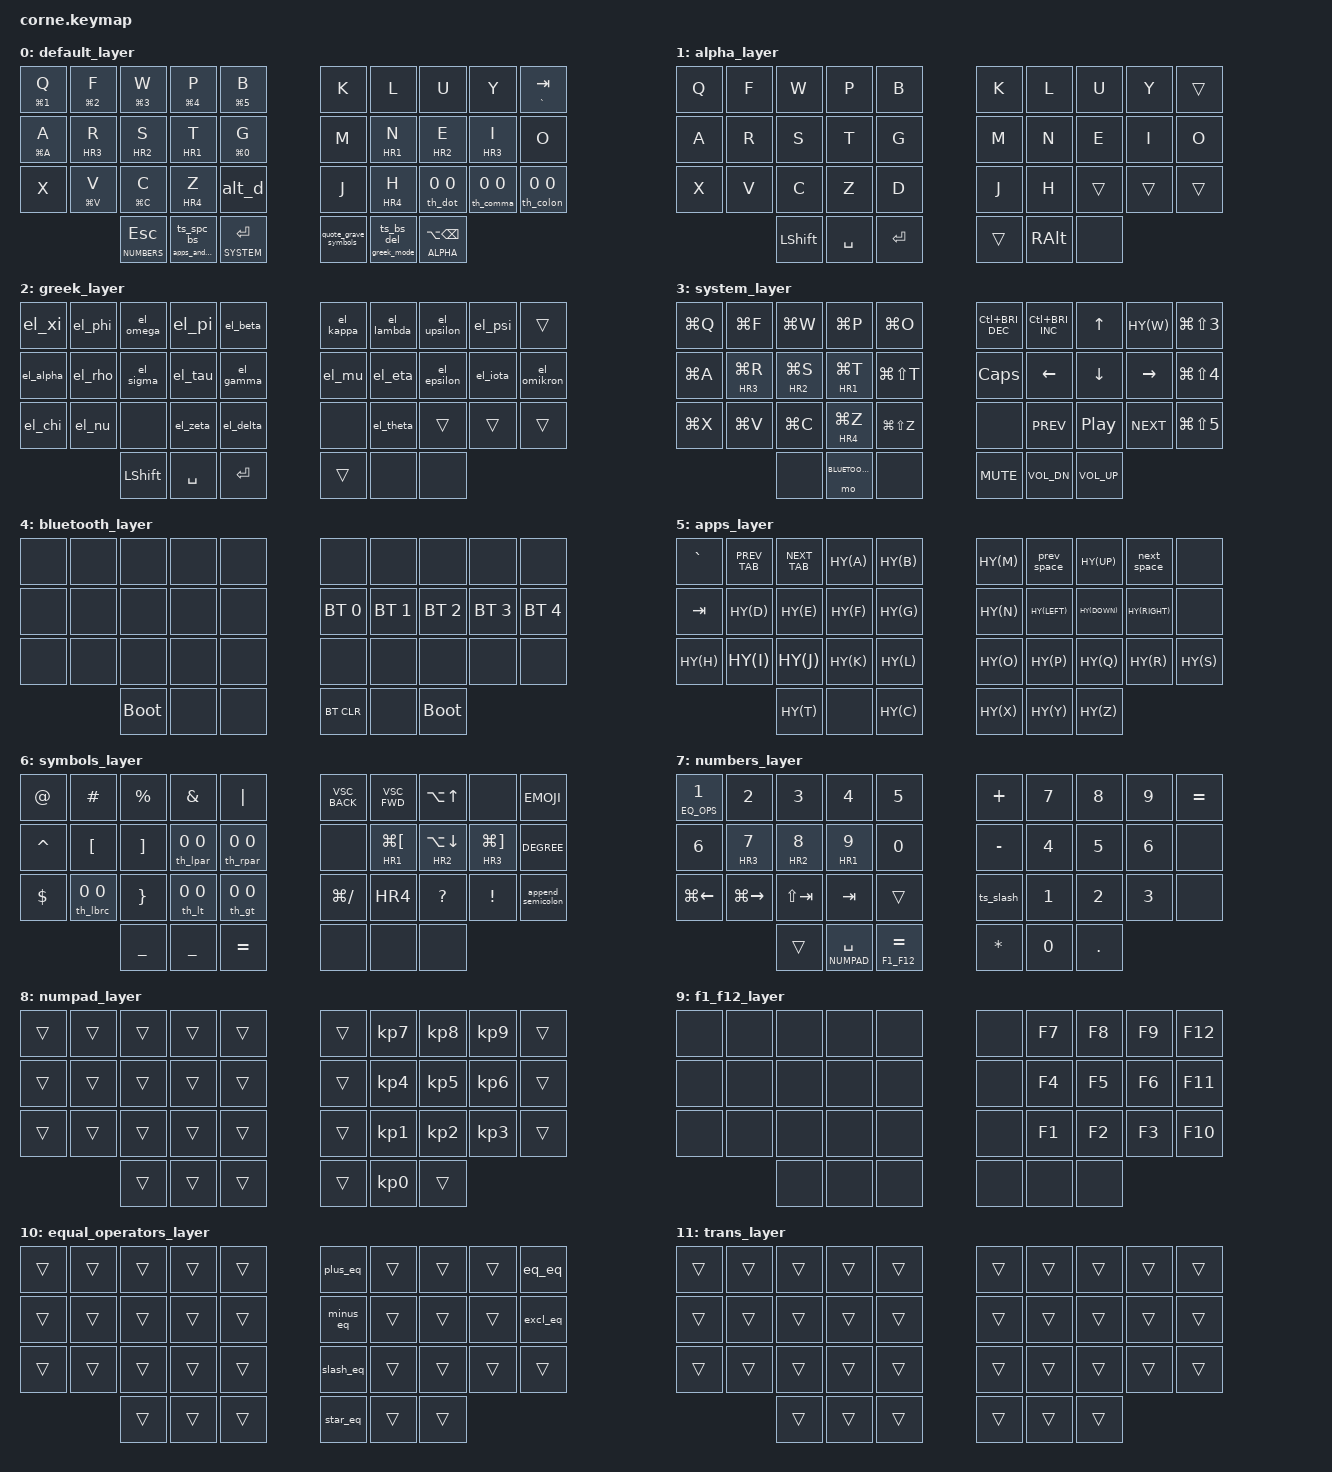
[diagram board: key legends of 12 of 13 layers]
#include <behaviors.dtsi>
#include <dt-bindings/zmk/keys.h>
#include <dt-bindings/zmk/bt.h>

#define HOST_OS 2
#include "zmk-helpers/helper.h"
#include "zmk-helpers/unicode-chars/greek.dtsi"

// layers
#define ALPHA 1
#define GREEK 2
#define SYSTEM 3
#define BLUETOOTH 4
#define APPS 5
#define SYMBOLS 6
#define NUMBERS 7
#define NUMPAD 8
#define F1_F12 9
#define EQ_OPS 10

// home row
#define HR1 LSHIFT
#define HR2 LCMD
#define HR3 RALT
#define HR4 LCTRL

#define PREV_TAB LG(LS(LBKT))
#define NEXT_TAB LG(LS(RBKT))

#define PREV_SPACE LC(LEFT)
#define NEXT_SPACE LC(RIGHT)

// VS Code
#define VSC_BACK LC(MINUS)
#define VSC_FWD LC(LS(MINUS))

#define HY(X) LA(LC(LG(LS(X))))
#define EMOJI LC(LG(SPACE))
#define DEGREE LA(LS(N8))


#define MAKE_TAP_SHIFT(name, tap, shift) \
    name: name { \
        compatible = "zmk,behavior-mod-morph"; \
        label = #name; \
        #binding-cells = <0>; \
        bindings = <&kp tap>, <&kp shift>; \
        mods = <(MOD_LSFT|MOD_RSFT)>; \
    };


#define MAKE_KP_MACRO(name, ...) \
    name: name { \
        label = #name; \
        compatible = "zmk,behavior-macro"; \
        #binding-cells = <0>; \
        wait-ms = <0>; \
        tap-ms = <0>; \
        bindings = <&macro_tap __VA_ARGS__>; \
    };


#define MAKE_EQ_MACRO(name, key) \
        MAKE_KP_MACRO(name, &kp SPACE &kp key &kp EQUAL &kp SPACE)


#define MAKE_TAP_HOLD(name, tap, hold) \
    name: name { \
        compatible = "zmk,behavior-hold-tap"; \
        label = #name; \
        #binding-cells = <2>; \
        flavor = "tap-preferred"; \
        tapping-term-ms = <200>; \
        bindings = <hold>, <tap>; \
    };


// fixes "system layer not activating" perceived bug
//
// > triggers the hold behavior when the tapping-term-ms has expired or another key is pressed
// > — https://zmk.dev/docs/behaviors/hold-tap#flavors
&lt {
    flavor = "hold-preferred";
};

// fixes "alt instead of apostrophe" bug
&mt {
    flavor = "tap-preferred";
};


/ {
    chosen {
        zmk,matrix_transform = &five_column_transform;
    };

    macros {
        // hold to enable apps layer and left command at the same time
        apps_and_lcmd: apps_and_lcmd {
            label = "apps_and_lcmd";
            compatible = "zmk,behavior-macro";
            #binding-cells = <0>;
            wait-ms = <0>;
            bindings
                = <&macro_press &mo APPS &kp LCMD>
                , <&macro_pause_for_release>
                , <&macro_release &mo APPS &kp LCMD>
                ;
        };

        // toggle unicode input mode and switch to the Greek layer
        greek_mode: greek_mode {
            label = "greek_mode";
            compatible = "zmk,behavior-macro";
            #binding-cells = <0>;
            wait-ms = <0>;
            bindings
                = <&macro_tap &kp HY(U)>  // Unicode (via Hammerspoon)
                , <&macro_press &mo GREEK>
                , <&macro_pause_for_release>
                , <&macro_release &mo GREEK>
                , <&macro_tap &kp HY(V)>  // Polish (via Hammerspoon)
                ;
        };


        MAKE_KP_MACRO(selfdot, &kp S &kp E &kp L &kp F &kp DOT)
        MAKE_KP_MACRO(thisdot, &kp T &kp H &kp I &kp S &kp DOT)
        MAKE_KP_MACRO(args0, &kp DOLLAR &kp N0 &kp DOT)
        MAKE_KP_MACRO(append_semicolon, &kp LG(RIGHT) &kp SEMICOLON)

        // macros for TypeScript "fat arrow": `() => { ... }`
        MAKE_KP_MACRO(short_arrow_close, &kp RIGHT &kp SPACE &kp EQUAL &kp GT &kp SPACE)
        MAKE_KP_MACRO(short_arrow, &kp LPAR &short_arrow_close)
        MAKE_KP_MACRO(fat_arrow_close, &short_arrow_close &kp LBRC &kp SPACE &kp LEFT &kp SPACE)
        MAKE_KP_MACRO(fat_arrow, &kp LPAR &fat_arrow_close)

        MAKE_KP_MACRO(braces, &kp LG(RIGHT) &kp SPACE &kp LBRC &kp ENTER)

        MAKE_EQ_MACRO(eq_eq, EQUAL)
        MAKE_EQ_MACRO(excl_eq, EXCLAMATION)
        MAKE_EQ_MACRO(plus_eq, PLUS)
        MAKE_EQ_MACRO(minus_eq, MINUS)
        MAKE_EQ_MACRO(slash_eq, SLASH)
        MAKE_EQ_MACRO(star_eq, ASTERISK)
    };

    behaviors {
        // https://zmk.dev/docs/behaviors/hold-tap#option-3-balanced
        bhm: balanced_homerow_mods {
            compatible = "zmk,behavior-hold-tap";
            label = "balanced_homerow_mods";
            #binding-cells = <2>;
            tapping-term-ms = <200>;
            quick-tap-ms = <0>;
            flavor = "balanced";
            bindings = <&kp>, <&kp>;
        };

        sbhm: sticky_balanced_homerow_mods {
            compatible = "zmk,behavior-hold-tap";
            label = "sticky_balanced_homerow_mods";
            #binding-cells = <2>;
            tapping-term-ms = <200>;
            quick-tap-ms = <0>;
            flavor = "balanced";
            bindings = <&sk>, <&kp>;
        };

        // `&lt` using `&apps_and_lcmd` and `&ts_spc_bs`
        // parameters are not used, so you can pass anything, e.g. 0 0
        MAKE_TAP_SHIFT(ts_spc_bs, SPACE, BACKSPACE)
        spc_bs_apps: spc_bs_apps {
            compatible = "zmk,behavior-hold-tap";
            label = "spc_bs_apps";
            #binding-cells = <2>;
            flavor = "hold-preferred";
            tapping-term-ms = <200>;
            bindings = <&apps_and_lcmd>, <&ts_spc_bs>;
        };

        // tap, alt+tap, hold
        quote_grave_symbols: quote_grave_symbols {
            compatible = "zmk,behavior-mod-morph";
            label = "quote_grave_symbols";
            #binding-cells = <0>;
            bindings = <&lt SYMBOLS SINGLE_QUOTE>, <&kp GRAVE>;
            mods = <(MOD_LALT|MOD_RALT)>;
        };

        // apps layer also holds down CMD, so I use a mod-morph to escape it
        prev_space: prev_space {
            compatible = "zmk,behavior-mod-morph";
            label = "prev_space";
            #binding-cells = <0>;
            bindings = <&kp PREV_SPACE>, <&kp PREV_SPACE>;
            mods = <(MOD_LGUI)>;
        };
        next_space: next_space {
            compatible = "zmk,behavior-mod-morph";
            label = "next_space";
            #binding-cells = <0>;
            bindings = <&kp NEXT_SPACE>, <&kp NEXT_SPACE>;
            mods = <(MOD_LGUI)>;
        };

        // tap, shift+tap, hold
        MAKE_TAP_SHIFT(ts_bs_del, BACKSPACE, DELETE)
        bs_del_greek: bs_del_greek {
            compatible = "zmk,behavior-hold-tap";
            label = "bs_del_greek";
            #binding-cells = <2>;
            flavor = "hold-preferred";
            tapping-term-ms = <200>;
            bindings = <&greek_mode>, <&ts_bs_del>;
        };

        // alt+d = alt+x
        alt_d: alt_d {
            compatible = "zmk,behavior-mod-morph";
            label = "alt_d";
            #binding-cells = <0>;
            bindings = <&kp D>, <&kp RA(X)>;
            mods = <(MOD_RALT)>;
        };

        // interpunction
        MAKE_TAP_SHIFT(ts_dot, DOT, QUESTION)
        MAKE_TAP_SHIFT(ts_comma, COMMA, EXCLAMATION)
        MAKE_TAP_SHIFT(ts_colon, COLON, SEMICOLON)

        // just a hack so that I can use `MAKE_TAP_HOLD` later on
        MAKE_TAP_SHIFT(ts_lbrc, LBRC, LBRC)
        MAKE_TAP_SHIFT(ts_lpar, LPAR, LPAR)
        MAKE_TAP_SHIFT(ts_rpar, RPAR, RPAR)
        MAKE_TAP_SHIFT(ts_lt, LT, LT)
        MAKE_TAP_SHIFT(ts_gt, GT, GT)

        // other
        MAKE_TAP_SHIFT(ts_slash, SLASH, BACKSLASH)

        // hold taps
        MAKE_TAP_HOLD(th_dot, &ts_dot, &selfdot)
        MAKE_TAP_HOLD(th_comma, &ts_comma, &thisdot)
        MAKE_TAP_HOLD(th_colon, &ts_colon, &args0)
        MAKE_TAP_HOLD(th_lbrc, &ts_lbrc, &braces)
        MAKE_TAP_HOLD(th_lpar, &ts_lpar, &fat_arrow)
        MAKE_TAP_HOLD(th_rpar, &ts_rpar, &fat_arrow_close)
        MAKE_TAP_HOLD(th_lt, &ts_lt, &short_arrow)
        MAKE_TAP_HOLD(th_gt, &ts_gt, &short_arrow_close)
    };

    keymap {
        compatible = "zmk,keymap";

        // Polemak: Colemak DH modified for Polish and Vim
        default_layer {
            bindings = <
&mt LG(N1) Q &mt LG(N2) F &mt LG(N3) W &mt LG(N4) P &mt LG(N5) B     &kp K &kp       L &kp      U  &kp       Y   &mt GRAVE TAB
&mt LG(A)  A &bhm HR3   R &bhm HR2   S &bhm HR1   T &mt LG(N0) G     &kp M &sbhm HR1 N &bhm HR2 E  &sbhm HR3 I   &kp O
&kp        X &mt LG(V)  V &mt LG(C)  C &bhm HR4   Z &alt_d           &kp J &bhm  HR4 H &th_dot 0 0 &th_comma 0 0 &th_colon 0 0
&lt NUMBERS ESC &spc_bs_apps 0 0 &lt SYSTEM ENTER                    &quote_grave_symbols &bs_del_greek 0 0 &lt ALPHA LA(BSPC)
            >;
        };

        alpha_layer {
            bindings = <
&kp Q &kp F &kp W &kp P &kp B     &kp K &kp L &kp U &kp Y &trans
&kp A &kp R &kp S &kp T &kp G     &kp M &kp N &kp E &kp I &kp O
&kp X &kp V &kp C &kp Z &kp D     &kp J &kp H &trans &trans &trans
&kp LSHIFT &kp SPACE &kp ENTER    &trans &kp RALT &none
            >;
        };

        greek_layer {
            bindings = <
&el_xi    &el_phi &el_omega &el_pi   &el_beta      &el_kappa &el_lambda &el_upsilon &el_psi  &trans
&el_alpha &el_rho &el_sigma &el_tau  &el_gamma     &el_mu    &el_eta    &el_epsilon &el_iota &el_omikron
&el_chi   &el_nu  &none     &el_zeta &el_delta     &none     &el_theta  &trans      &trans   &trans
&kp LSHIFT &kp SPACE &kp ENTER                     &trans &none &none
            >;
        };

        system_layer {
            bindings = <                                                                                                               /* screenshots */
&kp LG(Q) &kp      LG(F) &kp      LG(W) &kp      LG(P) &kp    LG(O)     &kp LC(C_BRI_DEC) &kp LC(C_BRI_INC) &kp UP           &kp HY(W)  &kp LG(LS(N3))
&kp LG(A) &bhm HR3 LG(R) &bhm HR2 LG(S) &bhm HR1 LG(T) &kp LG(LS(T))    &kp CAPSLOCK      &kp LEFT          &kp DOWN         &kp RIGHT  &kp LG(LS(N4))
&kp LG(X) &kp      LG(V) &kp      LG(C) &bhm HR4 LG(Z) &kp LG(LS(Z))    &none             &kp C_PREV        &kp C_PLAY_PAUSE &kp C_NEXT &kp LG(LS(N5))
                         &none          &mo BLUETOOTH  &none            &kp K_MUTE        &kp C_VOL_DN      &kp C_VOL_UP
            >;
        };

        bluetooth_layer {
            bindings = <
&none &none &none       &none &none    &none        &none        &none        &none        &none
&none &none &none       &none &none    &bt BT_SEL 0 &bt BT_SEL 1 &bt BT_SEL 2 &bt BT_SEL 3 &bt BT_SEL 4
&none &none &none       &none &none    &none        &none        &none        &none        &none
            &bootloader &none &none    &bt BT_CLR   &none        &bootloader
            >;
        };

        // powered by hammerspoon: https://github.com/narfdotpl/dotfiles/blob/master/home/.hammerspoon/init.lua
        apps_layer {
            bindings = <
&kp GRAVE &kp PREV_TAB &kp NEXT_TAB &kp HY(A) &kp HY(B)     &kp HY(M) &prev_space  &kp HY(UP)   &next_space   &none
&kp TAB   &kp HY(D)    &kp HY(E)    &kp HY(F) &kp HY(G)     &kp HY(N) &kp HY(LEFT) &kp HY(DOWN) &kp HY(RIGHT) &none
&kp HY(H) &kp HY(I)    &kp HY(J)    &kp HY(K) &kp HY(L)     &kp HY(O) &kp HY(P)    &kp HY(Q)    &kp HY(R)     &kp HY(S)
                       &kp HY(T)    &none     &kp HY(C)     &kp HY(X) &kp HY(Y)    &kp HY(Z)
            >;
        };

        symbols_layer {
            bindings = <
&kp AT     &kp HASH     &kp PERCENT &kp AMPS     &kp PIPE         &kp VSC_BACK  &kp VSC_FWD       &kp      LA(UP)   &none             &kp EMOJI
&kp CARET  &kp LBKT     &kp RBKT    &th_lpar 0 0 &th_rpar 0 0     &none         &bhm HR1 LG(LBKT) &bhm HR2 LA(DOWN) &bhm HR3 LG(RBKT) &kp DEGREE
&kp DOLLAR &th_lbrc 0 0 &kp RBRC    &th_lt 0 0   &th_gt 0 0       &kp LG(SLASH) &kp  HR4          &kp QUESTION      &kp EXCLAMATION   &append_semicolon
                        &kp UNDER   &kp UNDER    &kp EQUAL        &none         &none             &none
            >;
        };

        numbers_layer {
            bindings = <
&lt EQ_OPS N1 &kp      N2   &kp      N3 &kp      N4 &kp N5     &kp PLUS     &kp N7 &kp N8 &kp N9 &kp EQUAL
&kp        N6 &bhm HR3 N7   &bhm HR2 N8 &bhm HR1 N9 &kp N0     &kp MINUS    &kp N4 &kp N5 &kp N6 &none
&kp LG(LEFT)  &kp LG(RIGHT) &kp LS(TAB) &kp TAB     &trans     &ts_slash    &kp N1 &kp N2 &kp N3 &none
&trans        &lt NUMPAD SPACE &lt F1_F12 EQUAL                &kp ASTERISK &kp N0 &kp DOT
            >;
        };

        numpad_layer {
            bindings = <
&trans &trans &trans &trans &trans    &trans &kp KP_N7 &kp KP_N8 &kp KP_N9 &trans
&trans &trans &trans &trans &trans    &trans &kp KP_N4 &kp KP_N5 &kp KP_N6 &trans
&trans &trans &trans &trans &trans    &trans &kp KP_N1 &kp KP_N2 &kp KP_N3 &trans
              &trans &trans &trans    &trans &kp KP_N0 &trans
            >;
        };

        f1_f12_layer {
            bindings = <
&none &none &none &none &none    &none &kp F7 &kp F8 &kp F9 &kp F12
&none &none &none &none &none    &none &kp F4 &kp F5 &kp F6 &kp F11
&none &none &none &none &none    &none &kp F1 &kp F2 &kp F3 &kp F10
            &none &none &none    &none &none &none
            >;
        };

        equal_operators_layer {
            bindings = <
&trans &trans &trans &trans &trans    &plus_eq  &trans &trans &trans &eq_eq
&trans &trans &trans &trans &trans    &minus_eq &trans &trans &trans &excl_eq
&trans &trans &trans &trans &trans    &slash_eq &trans &trans &trans &trans
              &trans &trans &trans    &star_eq  &trans &trans
            >;
        };

        trans_layer {
            bindings = <
&trans &trans &trans &trans &trans    &trans &trans &trans &trans &trans
&trans &trans &trans &trans &trans    &trans &trans &trans &trans &trans
&trans &trans &trans &trans &trans    &trans &trans &trans &trans &trans
              &trans &trans &trans    &trans &trans &trans
            >;
        };

        none_layer {
            bindings = <
&none &none &none &none &none    &none &none &none &none &none
&none &none &none &none &none    &none &none &none &none &none
&none &none &none &none &none    &none &none &none &none &none
            &none &none &none    &none &none &none
            >;
        };
    };
};
